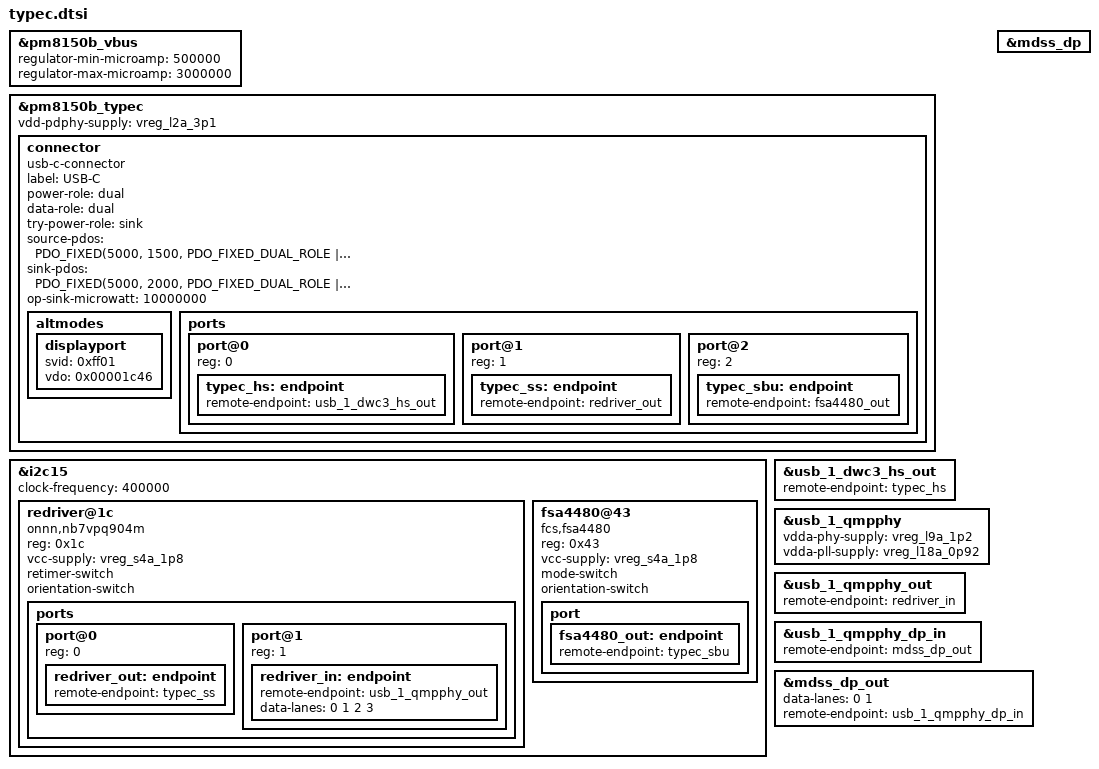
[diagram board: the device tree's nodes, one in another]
// SPDX-License-Identifier: BSD-3-Clause
/* DBY-W09: PM8150B TCPM, NB7VPQ904M SS redriver, FSA4480 AUX switch.
 * Stock i2c@884000, addresses 0x1c and 0x43; no enable GPIOs.
 */
&pm8150b_vbus {
	regulator-min-microamp = <500000>;
	regulator-max-microamp = <3000000>;
	status = "okay";
};

&pm8150b_typec {
	vdd-pdphy-supply = <&vreg_l2a_3p1>;
	status = "okay";
	connector {
		compatible = "usb-c-connector";
		label = "USB-C";
		power-role = "dual";
		data-role = "dual";
		try-power-role = "sink";
		source-pdos = <PDO_FIXED(5000, 1500, PDO_FIXED_DUAL_ROLE |
			PDO_FIXED_USB_COMM | PDO_FIXED_DATA_SWAP)>;
		sink-pdos = <PDO_FIXED(5000, 2000, PDO_FIXED_DUAL_ROLE |
			PDO_FIXED_USB_COMM | PDO_FIXED_DATA_SWAP)>;
		op-sink-microwatt = <10000000>;
		altmodes {
			displayport {
				svid = /bits/ 16 <0xff01>;
				vdo = <0x00001c46>;
			};
		};
		ports {
			#address-cells = <1>;
			#size-cells = <0>;
			port@0 {
				reg = <0>;
				typec_hs: endpoint { remote-endpoint = <&usb_1_dwc3_hs_out>; };
			};
			port@1 {
				reg = <1>;
				typec_ss: endpoint { remote-endpoint = <&redriver_out>; };
			};
			port@2 {
				reg = <2>;
				typec_sbu: endpoint { remote-endpoint = <&fsa4480_out>; };
			};
		};
	};
};

&i2c15 {
	clock-frequency = <400000>;
	status = "okay";
	redriver@1c {
		compatible = "onnn,nb7vpq904m";
		reg = <0x1c>;
		vcc-supply = <&vreg_s4a_1p8>;
		retimer-switch;
		orientation-switch;
		ports {
			#address-cells = <1>;
			#size-cells = <0>;
			port@0 {
				reg = <0>;
				redriver_out: endpoint { remote-endpoint = <&typec_ss>; };
			};
			port@1 {
				reg = <1>;
				redriver_in: endpoint {
					remote-endpoint = <&usb_1_qmpphy_out>;
					data-lanes = <0 1 2 3>;
				};
			};
		};
	};
	fsa4480@43 {
		compatible = "fcs,fsa4480";
		reg = <0x43>;
		vcc-supply = <&vreg_s4a_1p8>;
		mode-switch;
		orientation-switch;
		port {
			fsa4480_out: endpoint { remote-endpoint = <&typec_sbu>; };
		};
	};
};

&usb_1_dwc3_hs_out { remote-endpoint = <&typec_hs>; };
&usb_1_qmpphy {
	vdda-phy-supply = <&vreg_l9a_1p2>;
	vdda-pll-supply = <&vreg_l18a_0p92>;
	status = "okay";
};
&usb_1_qmpphy_out { remote-endpoint = <&redriver_in>; };
&usb_1_qmpphy_dp_in { remote-endpoint = <&mdss_dp_out>; };
&mdss_dp { status = "okay"; };
&mdss_dp_out {
	data-lanes = <0 1>;
	remote-endpoint = <&usb_1_qmpphy_dp_in>;
};
